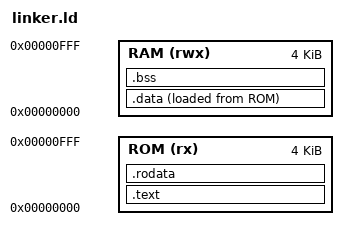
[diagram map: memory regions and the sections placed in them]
MEMORY
{
    ROM (rx) : ORIGIN = 0x00000000, LENGTH = 4K
    RAM (rwx) : ORIGIN = 0x00000000, LENGTH = 4K
}

SECTIONS
{
    .text :
    {
        . = ALIGN(4);
        *(.text)
        *(.text.*)
    } > ROM

    .rodata :
    {
        . = ALIGN(4);
        *(.rodata)
        *(.rodata.*)
    } > ROM

    .data :
    {
        . = ALIGN(4);
        _data_start = .;
        *(.data)
        *(.data.*)
        . = ALIGN(4);
        _data_end = .;
    } > RAM AT > ROM

    _data_load = LOADADDR(.data);

    .bss :
    {
        . = ALIGN(4);
        _bss_start = .;
        *(.bss)
        *(.bss.*)
        *(COMMON)
        . = ALIGN(4);
        _bss_end = .;
    } > RAM

    /DISCARD/ :
    {
        *(.comment)
        *(.note*)
    }
}
